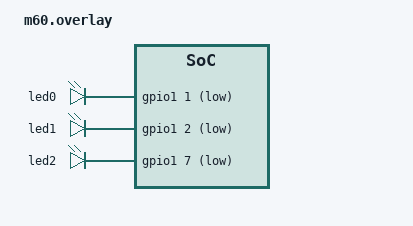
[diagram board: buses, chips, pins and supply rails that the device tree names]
#include <dt-bindings/zmk/matrix_transform.h>

/ {
    aliases {
        led-red = &led0;
        led-green = &led1;
        led-blue = &led2;
    };

    leds {
        compatible = "gpio-leds";
        status = "okay";
        led0: led_0 {
            gpios = <&gpio1 1 GPIO_ACTIVE_LOW>;
        };
        led1: led_1 {
            gpios = <&gpio1 2 GPIO_ACTIVE_LOW>;
        };
        led2: led_2 {
            gpios = <&gpio1 7 GPIO_ACTIVE_LOW>;
        };
    };
};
